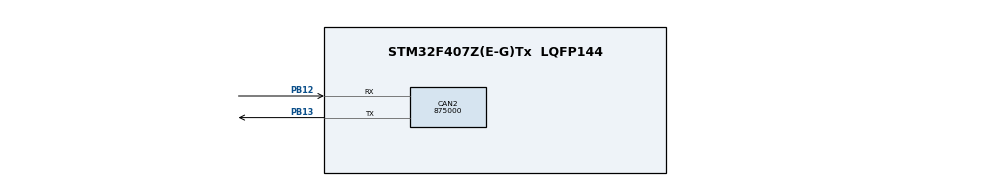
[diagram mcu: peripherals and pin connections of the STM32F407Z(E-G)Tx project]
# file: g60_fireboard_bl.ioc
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CAN2.CalculateBaudRate=875000
CAN2.CalculateTimeBit=1142
CAN2.CalculateTimeQuantum=380.95238095238096
Mcu.Family=STM32F4
Mcu.Name=STM32F407Z(E-G)Tx
Mcu.Package=LQFP144
NVIC.PriorityGroup=NVIC_PRIORITYGROUP_4
PA13.Mode=Serial_Wire
PA13.Signal=SYS_JTMS-SWDIO
PA14.Mode=Serial_Wire
PA14.Signal=SYS_JTCK-SWCLK
PB12.Mode=CAN_Activate
PB12.Signal=CAN2_RX
PB13.Mode=CAN_Activate
PB13.Signal=CAN2_TX
PH0-OSC_IN.Mode=HSE-External-Oscillator
PH0-OSC_IN.Signal=RCC_OSC_IN
PH1-OSC_OUT.Mode=HSE-External-Oscillator
PH1-OSC_OUT.Signal=RCC_OSC_OUT
ProjectManager.HeapSize=0x200
ProjectManager.StackSize=0x400
ProjectManager.TargetToolchain=MDK-ARM V5.32
RCC.48MHZClocksFreq_Value=24000000
RCC.AHBFreq_Value=84000000
RCC.APB1CLKDivider=RCC_HCLK_DIV2
RCC.APB1Freq_Value=42000000
RCC.APB1TimFreq_Value=84000000
RCC.APB2CLKDivider=RCC_HCLK_DIV2
RCC.APB2Freq_Value=42000000
RCC.APB2TimFreq_Value=84000000
RCC.CortexFreq_Value=84000000
RCC.HCLKFreq_Value=84000000
RCC.HSE_VALUE=25000000
RCC.HSI_VALUE=16000000
RCC.LSE_VALUE=32768
RCC.PLLM=8
RCC.PLLN=84
RCC.PLLQ=7
RCC.SYSCLKFreq_VALUE=84000000
RCC.SYSCLKSource=RCC_SYSCLKSOURCE_PLLCLK
RCC.VCOOutputFreq_Value=168000000
board=custom

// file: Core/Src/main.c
/* USER CODE BEGIN Header */
/**
  ******************************************************************************
  * @file           : main.c
  * @brief          : Main program body
  ******************************************************************************
  * @attention
  *
  * Copyright (c) 2024 STMicroelectronics.
  * All rights reserved.
  *
  * This software is licensed under terms that can be found in the LICENSE file
  * in the root directory of this software component.
  * If no LICENSE file comes with this software, it is provided AS-IS.
  *
  ******************************************************************************
  */
/* USER CODE END Header */
#include "main.h"
#include "can.h"
#include "gpio.h"

/* USER CODE BEGIN Includes */
#include "boot.h"
#include "ecc_test.h"
/* USER CODE END Includes */

void SystemClock_Config(void);

#if 0
static uint8_t adsdasda[1536] =
{
	0xF3,0xFF,0x0F,0xA6,0x9A,0x6B,0xC0,0xC3,0xF3,0x5A,0x56,
  0x97,0x3C,0xCF,0x33,0xA6,0x55,0x9B,0x3C,0x3F,0xFF,0xCF,
  0x0C,0x03,0xC3,0x0F,0x03,0x3F,0xF0,0x03,0x03,0x00,0xCF,
  0x65,0x56,0x9B,0x0F,0x30,0xFF,0x56,0x9A,0x5B,0x6A,0xA9,
  0xA7,0xC0,0xCC,0x0F,0xA6,0x95,0x9B,0xAA,0xA9,0x67,0x99,
  0x6A,0x97,0x69,0x99,0x97,0xAA,0x55,0x57,0xF0,0x3F,0xFF,
  0x0C,0xF3,0xCF,0x99,0x99,0x6B,0x6A,0x69,0x5B,0xF3,0x00,
  0x3F,0x03,0x00,0x33,0x00,0xCF,0xF3,0xC3,0x30,0x03,0xF3,
  0xC3,0xF3,0x55,0xA9,0x97,0x0F,0xC0,0xFF,0xA9,0x99,0x6B,
  0xAA,0xA9,0xAB,0x95,0x66,0x97,0x5A,0x9A,0x67,0xAA,0x99,
  0x67,0x96,0x99,0x97,0x56,0x99,0x6B,0x5A,0x5A,0x9B,0x59,
  0xA5,0x67,0x95,0x99,0x67,0x66,0x96,0x9B,0xC0,0xCC,0xFF,
  0xFF,0xC3,0xFF,0x69,0x99,0x6B,0x56,0xAA,0x57,0xC0,0xCC,
  0xFF,0x56,0xA5,0xAB,0x30,0xCC,0xC3,0x6A,0xAA,0x57,0xFC,
  0xFC,0xFF,0xFC,0xF3,0xF3,0x0F,0x3C,0xFF,0xFC,0x03,0xC3,
  0x00,0xF0,0x03,0xA5,0x95,0x67,0x0F,0x3F,0xC3,0x95,0x99,
  0xA7,0x6A,0x56,0xA7,0xC0,0xF3,0x33,0x56,0x6A,0xA7,0x3F,
  0x03,0x03,0xF3,0xF3,0x3F,0x6A,0xA9,0x5B,0x00,0x0C,0x03,
  0xCF,0xCC,0x03,0x0F,0xFC,0x0F,0xFF,0xFF,0xFF,0xFF,0xFF,
	0xFF,0xFF,0xFF,0xFF,0xFF,0xFF,0xFF,0xFF,0xFF,0xFF,0xFF,
	0xFF,0xFF,0xFF,0xFF,0xFF,0xFF,0xFF,0xFF,0xFF,0xFF,0xFF,
	0xFF,0xFF,0xFF,0xFF,0xFF,0xFF,0xFF,0xFF,0xFF,0xFF,0xFF,
	0xFF,0xFF,0xFF,0xFF,0xFF,0xFF,0xFF,0xFF,0xFF,0xFF,0xFF,
	0xFF,0xFF,0xFF,0xFF,0xFF,0xFF,0xFF,0xFF,0xFF,0xFF,0xFF,
	0xFF,0xFF,0xFF,0xFF,0xFF,0xFF,0xFF,0xFF,0xFF,0xFF,0xFF,
	0xFF,0xFF,0xFF,0xFF,0xFF,0xFF,0xFF,0xFF,0xFF,0xFF,0xFF,
	0xFF,0xFF,0xFF,0xFF,0xFF,0xFF,0xFF,0xFF,0xFF,0xFF,0xFF,
	0xFF,0xFF,0xFF,0xFF,0xFF,0xFF,0xFF,0xFF,0xFF,0xFF,0xFF,
	0xFF,0xFF,0xFF,0xFF,0xFF,0xFF,0xFF,0xFF,0xFF,0xFF,0xFF,
	0xFF,0xFF,0xFF,0xFF,0xFF,0xFF,0xFF,0xFF,0xFF,0xFF,0xFF,
	0xFF,0xFF,0xFF,0xFF,0xFF,0xFF,0xFF,0xFF,0xFF,0xFF,0xFF,
	0xFF,0xFF,0xFF,0xFF,0xFF,0xFF,0xFF,0xFF,0xFF,0xFF,0xFF,
	0xFF,0xFF,0xFF,0xFF,0xFF,0xFF,0xFF,0xFF,0xFF,0xFF,0xFF,
	0xFF,0xFF,0xFF,0xFF,0xFF,0xFF,0xFF,0xFF,0xFF,0xFF,0xFF,
	0xFF,0xFF,0xFF,0xFF,0xFF,0xFF,0xFF,0xFF,0xFF,0xFF,0xFF,
	0xFF,0xFF,0xFF,0xFF,0xFF,0xFF,0xFF,0xFF,0xFF,0xFF,0xFF,
	0xFF,0xFF,0xFF,0xFF,0xFF,0xFF,0xFF,0xFF,0xFF,0xFF,0xFF,
	0xFF,0xFF,0xFF,0xFF,0xFF,0xFF,0xFF,0xFF,0xFF,0xFF,0xFF,
	0xFF,0xFF,0xFF,0xFF,0xFF,0xFF,0xFF,0xFF,0xFF,0xFF,0xFF,
	0xFF,0xFF,0xFF,0xFF,0xFF,0xFF,0xFF,0xFF,0xFF,0xFF,0xFF,
	0xFF,0xFF,0xFF,0xFF,0xFF,0xFF,0xFF,0xFF,0xFF,0xFF,0xFF,
	0xFF,0xFF,0xFF,0xFF,0xFF,0xFF,0xFF,0xFF,0xFF,0xFF,0xFF,
	0xFF,0xFF,0xFF,0xFF,0xFF,0xFF,0xFF,0xFF,0xFF,0xFF,0xFF,
	0xFF,0xFF,0xFF,0xFF,0xFF,0xFF,0xFF,0xFF,0xFF,0xFF,0xFF,
	0xFF,0xFF,0xFF,0xFF,0xFF,0xFF,0xFF,0xFF,0xFF,0xFF,0xFF,
	0xFF,0xFF,0xFF,0xFF,0xFF,0xFF,0xFF,0xFF,0xFF,0xFF,0xFF,
	0xFF,0xFF,0xFF,0xFF,0xFF,0xFF,0xFF,0xFF,0xFF,0xFF,0xFF,
	0xFF,0xFF,0xFF,0xFF,0xFF,0xFF,0xFF,0xFF,0xFF,0xFF,0xFF,
	0xFF,0xFF,0xFF,0xFF,0xFF,0xFF,0xFF,0xFF,0xFF,0xFF,0xFF,
	0xFF,0xFF,0xFF,0xFF,0xFF,0xFF,0xFF,0xFF,0xFF,0xFF,0xFF,
	0xFF,0xFF,0xFF,0xFF,0xFF,0xFF,0xFF,0xFF,0xFF,0xFF,0xFF,
	0xFF,0xFF,0xFF,0xFF,0xFF,0xFF,0xFF,0xFF,0xFF,0xFF,0xFF,
	0xFF,0xFF,0xFF,0xFF,0xFF,0xFF,0xFF,0xFF,0xFF,0xFF,0xFF,
	0xFF,0xFF,0xFF,0xFF,0xFF,0xFF,0xFF,0xFF,0xFF,0xFF,0xFF,
	0xFF,0xFF,0xFF,0xFF,0xFF,0xFF,0xFF,0xFF,0xFF,0xFF,0xFF,
	0xFF,0xFF,0xFF,0xFF,0xFF,0xFF,0xFF,0xFF,0xFF,0xFF,0xFF,
	0xFF,0xFF,0xFF,0xFF,0xFF,0xFF,0xFF,0xFF,0xFF,0xFF,0xFF,
	0xFF,0xFF,0xFF,0xFF,0xFF,0xFF,0xFF,0xFF,0xFF,0xFF,0xFF,
	0xFF,0xFF,0xFF,0xFF,0xFF,0xFF,0xFF,0xFF,0xFF,0xFF,0xFF,
	0xFF,0xFF,0xFF,0xFF,0xFF,0xFF,0xFF,0xFF,0xFF,0xFF,0xFF,
	0xFF,0xFF,0xFF,0xFF,0xFF,0xFF,0xFF,0xFF,0xFF,0xFF,0xFF,
	0xFF,0xFF,0xFF,0xFF,0xFF,0xFF,0xFF,0xFF,0xFF,0xFF,0xFF,
	0xFF,0xFF,0xFF,0xFF,0xFF,0xFF,0xFF,0xFF,0xFF,0xFF,0xFF,
	0xFF,0xFF,0xFF,0xFF,0xFF,0xFF,0xFF,0xFF,0xFF,0xFF,0xFF,
	0xFF,0xFF,0xFF,0xFF,0xFF,0xFF,0xFF,0xFF,0xFF,0xFF,0xFF,
	0xFF,0xFF,0xFF,0xFF,0xFF,0xFF,0xFF,0xFF,0xFF,0xFF,0xFF,
	0xFF,0xFF,0xFF,0xFF,0xFF,0xFF,0xFF,0xFF,0xFF,0xFF,0xFF,
	0xFF,0xFF,0xFF,0xFF,0xFF,0xFF,0xFF,0xFF,0xFF,0xFF,0xFF,
	0xFF,0xFF,0xFF,0xFF,0xFF,0xFF,0xFF,0xFF,0xFF,0xFF,0xFF,
	0xFF,0xFF,0xFF,0xFF,0xFF,0xFF,0xFF,0xFF,0xFF,0xFF,0xFF,
	0xFF,0xFF,0xFF,0xFF,0xFF,0xFF,0xFF,0xFF,0xFF,0xFF,0xFF,
	0xFF,0xFF,0xFF,0xFF,0xFF,0xFF,0xFF,0xFF,0xFF,0xFF,0xFF,
	0xFF,0xFF,0xFF,0xFF,0xFF,0xFF,0xFF,0xFF,0xFF,0xFF,0xFF,
	0xFF,0xFF,0xFF,0xFF,0xFF,0xFF,0xFF,0xFF,0xFF,0xFF,0xFF,
	0xFF,0xFF,0xFF,0xFF,0xFF,0xFF,0xFF,0xFF,0xFF,0xFF,0xFF,
	0xFF,0xFF,0xFF,0xFF,0xFF,0xFF,0xFF,0xFF,0xFF,0xFF,0xFF,
	0xFF,0xFF,0xFF,0xFF,0xFF,0xFF,0xFF,0xFF,0xFF,0xFF,0xFF,
	0xFF,0xFF,0xFF,0xFF,0xFF,0xFF,0xFF,0xFF,0xFF,0xFF,0xFF,
	0xFF,0xFF,0xFF,0xFF,0xFF,0xFF,0xFF,0xFF,0xFF,0xFF,0xFF,
	0xFF,0xFF,0xFF,0xFF,0xFF,0xFF,0xFF,0xFF,0xFF,0xFF,0xFF,
	0xFF,0xFF,0xFF,0xFF,0xFF,0xFF,0xFF,0xFF,0xFF,0xFF,0xFF,
	0xFF,0xFF,0xFF,0xFF,0xFF,0xFF,0xFF,0xFF,0xFF,0xFF,0xFF,
	0xFF,0xFF,0xFF,0xFF,0xFF,0xFF,0xFF,0xFF,0xFF,0xFF,0xFF,
	0xFF,0xFF,0xFF,0xFF,0xFF,0xFF,0xFF,0xFF,0xFF,0xFF,0xFF,
	0xFF,0xFF,0xFF,0xFF,0xFF,0xFF,0xFF,0xFF,0xFF,0xFF,0xFF,
	0xFF,0xFF,0xFF,0xFF,0xFF,0xFF,0xFF,0xFF,0xFF,0xFF,0xFF,
	0xFF,0xFF,0xFF,0xFF,0xFF,0xFF,0xFF,0xFF,0xFF,0xFF,0xFF,
	0xFF,0xFF,0xFF,0xFF,0xFF,0xFF,0xFF,0xFF,0xFF,0xFF,0xFF,
	0xFF,0xFF,0xFF,0xFF,0xFF,0xFF,0xFF,0xFF,0xFF,0xFF,0xFF,
	0xFF,0xFF,0xFF,0xFF,0xFF,0xFF,0xFF,0xFF,0xFF,0xFF,0xFF,
	0xFF,0xFF,0xFF,0xFF,0xFF,0xFF,0xFF,0xFF,0xFF,0xFF,0xFF,
	0xFF,0xFF,0xFF,0xFF,0xFF,0xFF,0xFF,0xFF,0xFF,0xFF,0xFF,
	0xFF,0xFF,0xFF,0xFF,0xFF,0xFF,0xFF,0xFF,0xFF,0xFF,0xFF,
	0xFF,0xFF,0xFF,0xFF,0xFF,0xFF,0xFF,0xFF,0xFF,0xFF,0xFF,
	0xFF,0xFF,0xFF,0xFF,0xFF,0xFF,0xFF,0xFF,0xFF,0xFF,0xFF,
	0xFF,0xFF,0xFF,0xFF,0xFF,0xFF,0xFF,0xFF,0xFF,0xFF,0xFF,
	0xFF,0xFF,0xFF,0xFF,0xFF,0xFF,0xFF,0xFF,0xFF,0xFF,0xFF,
	0xFF,0xFF,0xFF,0xFF,0xFF,0xFF,0xFF,0xFF,0xFF,0xFF,0xFF,
	0xFF,0xFF,0xFF,0xFF,0xFF,0xFF,0xFF,0xFF,0xFF,0xFF,0xFF,
	0xFF,0xFF,0xFF,0xFF,0xFF,0xFF,0xFF,0xFF,0xFF,0xFF,0xFF,
	0xFF,0xFF,0xFF,0xFF,0xFF,0xFF,0xFF,0xFF,0xFF,0xFF,0xFF,
	0xFF,0xFF,0xFF,0xFF,0xFF,0xFF,0xFF,0xFF,0xFF,0xFF,0xFF,
	0xFF,0xFF,0xFF,0xFF,0xFF,0xFF,0xFF,0xFF,0xFF,0xFF,0xFF,
	0xFF,0xFF,0xFF,0xFF,0xFF,0xFF,0xFF,0xFF,0xFF,0xFF,0xFF,
	0xFF,0xFF,0xFF,0xFF,0xFF,0xFF,0xFF,0xFF,0xFF,0xFF,0xFF,
	0xFF,0xFF,0xFF,0xFF,0xFF,0xFF,0xFF,0xFF,0xFF,0xFF,0xFF,
	0xFF,0xFF,0xFF,0xFF,0xFF,0xFF,0xFF,0xFF,0xFF,0xFF,0xFF,
	0xFF,0xFF,0xFF,0xFF,0xFF,0xFF,0xFF,0xFF,0xFF,0xFF,0xFF,
	0xFF,0xFF,0xFF,0xFF,0xFF,0xFF,0xFF,0xFF,0xFF,0xFF,0xFF,
	0xFF,0xFF,0xFF,0xFF,0xFF,0xFF,0xFF,0xFF,0xFF,0xFF,0xFF,
	0xFF,0xFF,0xFF,0xFF,0xFF,0xFF,0xFF,0xFF,0xFF,0xFF,0xFF,
	0xFF,0xFF,0xFF,0xFF,0xFF,0xFF,0xFF,0xFF,0xFF,0xFF,0xFF,
	0xFF,0xFF,0xFF,0xFF,0xFF,0xFF,0xFF,0xFF,0xFF,0xFF,0xFF,
	0xFF,0xFF,0xFF,0xFF,0xFF,0xFF,0xFF,0xFF,0xFF,0xFF,0xFF,
	0xFF,0xFF,0xFF,0xFF,0xFF,0xFF,0xFF,0xFF,0xFF,0xFF,0xFF,
	0xFF,0xFF,0xFF,0xFF,0xFF,0xFF,0xFF,0xFF,0xFF,0xFF,0xFF,
	0xFF,0xFF,0xFF,0xFF,0xFF,0xFF,0xFF,0xFF,0xFF,0xFF,0xFF,
	0xFF,0xFF,0xFF,0xFF,0xFF,0xFF,0xFF,0xFF,0xFF,0xFF,0xFF,
	0xFF,0xFF,0xFF,0xFF,0xFF,0xFF,0xFF,0xFF,0xFF,0xFF,0xFF,
	0xFF,0xFF,0xFF,0xFF,0xFF,0xFF,0xFF,0xFF,0xFF,0xFF,0xFF,
	0xFF,0xFF,0xFF,0xFF,0xFF,0xFF,0xFF,0xFF,0xFF,0xFF,0xFF,
	0xFF,0xFF,0xFF,0xFF,0xFF,0xFF,0xFF,0xFF,0xFF,0xFF,0xFF,
	0xFF,0xFF,0xFF,0xFF,0xFF,0xFF,0xFF,0xFF,0xFF,0xFF,0xFF,
	0xFF,0xFF,0xFF,0xFF,0xFF,0xFF,0xFF,0xFF,0xFF,0xFF,0xFF,
	0xFF,0xFF,0xFF,0xFF,0xFF,0xFF,0xFF,0xFF,0xFF,0xFF,0xFF,
	0xFF,0xFF,0xFF,0xFF,0xFF,0xFF,0xFF,0xFF,0xFF,0xFF,0xFF,
	0xFF,0xFF,0xFF,0xFF,0xFF,0xFF,0xFF,0xFF,0xFF,0xFF,0xFF,
	0xFF,0xFF,0xFF,0xFF,0xFF,0xFF,0xFF,0xFF,0xFF,0xFF,0xFF,
	0xFF,0xFF,0xFF,0xFF,0xFF,0xFF,0xFF,0xFF,0xFF,0xFF,0xFF,
	0xFF,0xFF,0xFF,0xFF,0xFF,0xFF,0xFF,0xFF,0xFF,0xFF,0xFF,
	0xFF,0xFF,0xFF,0xFF,0xFF,0xFF,0xFF,0xFF,0xFF,0xFF,0xFF,
	0xFF,0xFF,0xFF,0xFF,0xFF,0xFF,0xFF,0xFF,0xFF,0xFF,0xFF,
	0xFF,0xFF,0xFF,0xFF,0xFF,0xFF,0xFF,0xFF,0xFF,0xFF,0xFF,
	0xFF,0xFF,0xFF,0xFF,0xFF,0xFF,0xFF,0xFF,0xFF,0xFF,0xFF,
	0xFF,0xFF,0xFF,0xFF,0xFF,0xFF,0xFF,0xFF,0xFF,0xFF,0xFF,
	0xFF,0xFF,0xFF,0xFF,0xFF,0xFF,0xFF,0xFF,0xFF,0xFF,0xFF,
	0xFF,0xFF,0xFF,0xFF,0xFF,0xFF,0xFF,0xFF,0xFF,0xFF,0xFF,
	0xFF,0xFF,0xFF,0xFF,0xFF,0xFF,0xFF,0xFF,0xFF,0xFF,0xFF,
	0xFF,0xFF,0xFF,0xFF,0xFF,0xFF,0x9A,0xAA,0x5B,0xFF,0xFF,
  0xFF,0xFF,0xFF,0xFF,0xFF,0xFF,0xFF,
};
#endif
int main(void)
{

  /* MCU Configuration--------------------------------------------------------*/

  /* Reset of all peripherals, Initializes the Flash interface and the Systick. */
  HAL_Init();

  /* Configure the system clock */
  SystemClock_Config();

  /* Initialize all configured peripherals */
  MX_GPIO_Init();
  MX_CAN2_Init();
  /* USER CODE BEGIN 2 */

#if DH_ECC_ENABLE
	if(BOOT_ENTER_BOOT != dh_bootup_process_retry())
	{
		//ecc test ， only test FLASH_APP_BK0_ADDR zone，and repair
		//dh_write_flash_data(FLASH_ECC_INF_ADDR, adsdasda, sizeof(adsdasda));
		dh_ecc_repair_process();
	}
#else
	dh_bootup_process_retry();
#endif
  /* USER CODE END 2 */

  /* Infinite loop */
  while (1)
  {

  }
}

void SystemClock_Config(void)
{
  LL_FLASH_SetLatency(LL_FLASH_LATENCY_2);
  while(LL_FLASH_GetLatency()!= LL_FLASH_LATENCY_2)
  {
  }
  LL_PWR_SetRegulVoltageScaling(LL_PWR_REGU_VOLTAGE_SCALE1);
  LL_RCC_HSI_SetCalibTrimming(16);
  LL_RCC_HSI_Enable();

   /* Wait till HSI is ready */
  while(LL_RCC_HSI_IsReady() != 1)
  {

  }
  LL_RCC_PLL_ConfigDomain_SYS(LL_RCC_PLLSOURCE_HSI, LL_RCC_PLLM_DIV_8, 84, LL_RCC_PLLP_DIV_2);
  LL_RCC_PLL_Enable();

   /* Wait till PLL is ready */
  while(LL_RCC_PLL_IsReady() != 1)
  {

  }
  LL_RCC_SetAHBPrescaler(LL_RCC_SYSCLK_DIV_1);
  LL_RCC_SetAPB1Prescaler(LL_RCC_APB1_DIV_2);
  LL_RCC_SetAPB2Prescaler(LL_RCC_APB2_DIV_2);
  LL_RCC_SetSysClkSource(LL_RCC_SYS_CLKSOURCE_PLL);

   /* Wait till System clock is ready */
  while(LL_RCC_GetSysClkSource() != LL_RCC_SYS_CLKSOURCE_STATUS_PLL)
  {

  }
  LL_SetSystemCoreClock(84000000);

   /* Update the time base */
  if (HAL_InitTick (TICK_INT_PRIORITY) != HAL_OK)
  {
    Error_Handler();
  }
}

void Error_Handler(void)
{
  __disable_irq();
  while (1)
  {
  }
}
